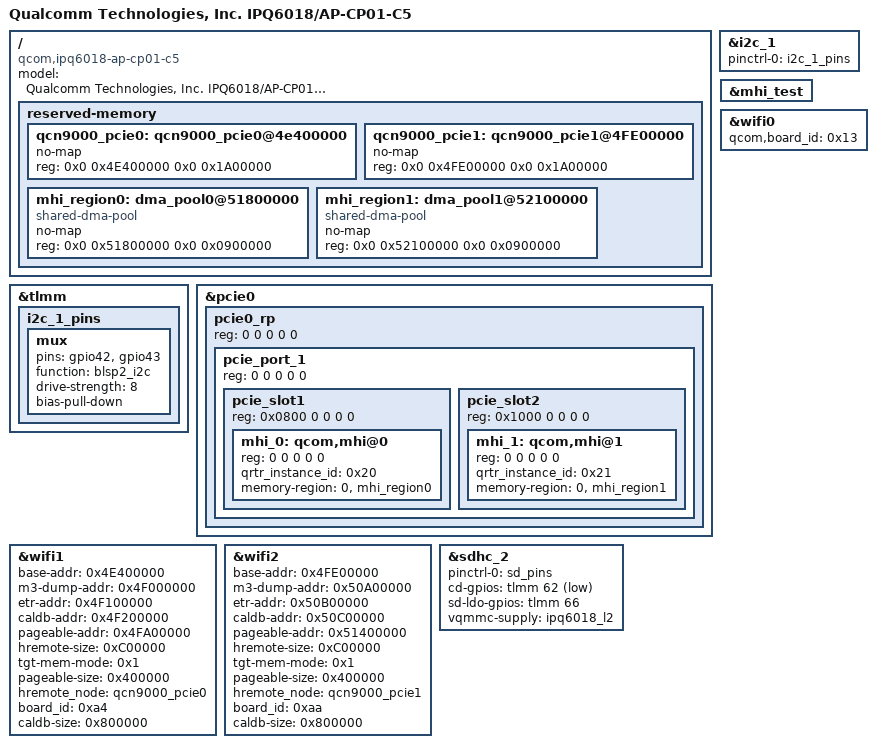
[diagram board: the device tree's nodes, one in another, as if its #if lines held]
/dts-v1/;
/*
 * Copyright (c) 2019, 2021 The Linux Foundation. All rights reserved.
 *
 * Permission to use, copy, modify, and/or distribute this software for any
 * purpose with or without fee is hereby granted, provided that the above
 * copyright notice and this permission notice appear in all copies.
 *
 * THE SOFTWARE IS PROVIDED "AS IS" AND THE AUTHOR DISCLAIMS ALL WARRANTIES
 * WITH REGARD TO THIS SOFTWARE INCLUDING ALL IMPLIED WARRANTIES OF
 * MERCHANTABILITY AND FITNESS. IN NO EVENT SHALL THE AUTHOR BE LIABLE FOR
 * ANY SPECIAL, DIRECT, INDIRECT, OR CONSEQUENTIAL DAMAGES OR ANY DAMAGES
 * WHATSOEVER RESULTING FROM LOSS OF USE, DATA OR PROFITS, WHETHER IN AN
 * ACTION OF CONTRACT, NEGLIGENCE OR OTHER TORTIOUS ACTION, ARISING OUT OF
 * OR IN CONNECTION WITH THE USE OR PERFORMANCE OF THIS SOFTWARE.
 */

#include "ipq6018-cp01.dtsi"
#include "ipq6018-cpr-regulator.dtsi"

/ {
	model = "Qualcomm Technologies, Inc. IPQ6018/AP-CP01-C5";
	compatible = "qcom,ipq6018-ap-cp01-c5", "qcom,ipq6018-ap-cp01", "qcom,ipq6018";

	reserved-memory {

/* No Pine attach in 256M profile */
#if !defined(__IPQ_MEM_PROFILE_256_MB__)
#ifdef __IPQ_MEM_PROFILE_512_MB__
		/*	    512 MB Profile for cp01-c3
		 * +========+==============+=========================+
		 * | Region | Start Offset |          Size           |
		 * +--------+--------------+-------------------------+
		 * |  NSS   |  0x40000000  |          16MB           |
		 * +--------+--------------+-------------------------+
		 * |        |              |                         |
		 * | Linux  |  0x41000000  |         145MB           |
		 * |        |              |                         |
		 * +--------+--------------+-------------------------+
		 * | uboot  |  0x4A100000  |           4MB           |
		 * +--------+--------------+-------------------------+
		 * |  SBL   |  0x4A500000  |           1MB           |
		 * +--------+--------------+-------------------------+
		 * | TZ+HYP |  0x4A600000  |           4MB           |
		 * +--------+--------------+-------------------------+
		 * |  smem  |  0x4AA00000  |           1MB           |
		 * +--------+--------------+-------------------------+
		 * |   Q6   |  0x4AB00000  |          55MB           |
		 * +--------+--------------+-------------------------+
		 * |  QDSS  |  0x4E200000  |           1MB           |
		 * +--------+--------------+-------------------------+
		 * | M3 Dump|  0x4E300000  |           1MB           |
		 * +--------+--------------+-------------------------+
		 * |  Pine0 |  0x4E400000  |          26MB           |
		 * +--------+--------------+-------------------------+
		 * |  Pine1 |  0x4FE00000  |          26MB           |
		 * +--------+--------------+-------------------------+
		 * |  MHI0  |  0x51800000  |           9MB           |
		 * +--------+--------------+-------------------------+
		 * |  MHI1  |  0x52100000  |           9MB           |
		 * +=================================================+
		 * |           Remaining memory for Linux            |
		 * +=================================================+
		 */
		qcn9000_pcie0: qcn9000_pcie0@4e400000 {
			no-map;
			reg = <0x0 0x4E400000 0x0 0x1A00000>;
		};

		qcn9000_pcie1: qcn9000_pcie1@4FE00000 {
			no-map;
			reg = <0x0 0x4FE00000 0x0 0x1A00000>;
		};

#if defined(__CNSS2__)
		mhi_region0: dma_pool0@51800000 {
			compatible = "shared-dma-pool";
			no-map;
			reg = <0x0 0x51800000 0x0 0x0900000>;
		};

		mhi_region1: dma_pool1@52100000 {
			compatible = "shared-dma-pool";
			no-map;
			reg = <0x0 0x52100000 0x0 0x0900000>;
		};
#endif
#else
		/*		  Default Profile
		 * +========+==============+=========================+
		 * | Region | Start Offset |          Size           |
		 * +--------+--------------+-------------------------+
		 * |  NSS   |  0x40000000  |          16MB           |
		 * +--------+--------------+-------------------------+
		 * | Linux  |  0x41000000  |         145MB           |
		 * +--------+--------------+-------------------------+
		 * | uboot  |  0x4A100000  |           4MB           |
		 * +--------+--------------+-------------------------+
		 * |  SBL   |  0x4A500000  |           1MB           |
		 * +--------+--------------+-------------------------+
		 * | TZ+HYP |  0x4A600000  |           4MB           |
		 * +--------+--------------+-------------------------+
		 * |  smem  |  0x4AA00000  |           1MB           |
		 * +--------+--------------+-------------------------+
		 * |   Q6   |  0x4AB00000  |          85MB           |
		 * +--------+--------------+-------------------------+
		 * |  QDSS  |  0x50000000  |           1MB           |
		 * +--------+--------------+-------------------------+
		 * | M3 Dump|  0x50100000  |           1MB           |
		 * +--------+--------------+-------------------------+
		 * |  Pine0 |  0x50200000  |          53MB           |
		 * +--------+--------------+-------------------------+
		 * |  Pine1 |  0x53700000  |          53MB           |
		 * +--------+--------------+-------------------------+
		 * |  MHI0  |  0x56C00000  |           9MB           |
		 * +--------+--------------+-------------------------+
		 * |  MHI1  |  0x57500000  |           9MB           |
		 * +=================================================+
		 * |           Remaining memory for Linux            |
		 * +=================================================+
		 */
		qcn9000_pcie0: qcn9000_pcie0@50200000 {
			no-map;
			reg = <0x0 0x50200000 0x0 0x03500000>;
		};

		qcn9000_pcie1: qcn9000_pcie1@53700000 {
			no-map;
			reg = <0x0 0x53700000 0x0 0x03500000>;
		};

#if defined(__CNSS2__)
		mhi_region0: dma_pool0@56c00000 {
			compatible = "shared-dma-pool";
			no-map;
			reg = <0x0 0x56C00000 0x0 0x00900000>;
		};

		mhi_region1: dma_pool1@57500000 {
			compatible = "shared-dma-pool";
			no-map;
			reg = <0x0 0x57500000 0x0 0x00900000>;
		};
#endif
#endif
#endif
	};
};

&tlmm {
	i2c_1_pins: i2c_1_pins {
		mux {
			pins = "gpio42", "gpio43";
			function = "blsp2_i2c";
			drive-strength = <8>;
			bias-pull-down;
		};
	};
};

&i2c_1 {
	pinctrl-0 = <&i2c_1_pins>;
	pinctrl-names = "default";
	status = "ok";
};

&pcie0 {
	pcie0_rp {
		reg = <0 0 0 0 0>;
		status = "ok";
		device_type = "pci";

		pcie_port_1: pcie_port_1 {
			reg = <0 0 0 0 0>;
			device_type = "pci";

			pcie_slot1: pcie_slot1 {
				reg = <0x0800 0 0 0 0>;
				device_type = "pci";
			};

			pcie_slot2: pcie_slot2 {
				reg = <0x1000 0 0 0 0>;
				device_type = "pci";
			};
		};
	};
};

&pcie_port_1 {
	status = "ok";
};

&pcie_slot1 {
	status = "ok";

	mhi_0: qcom,mhi@0 {
		reg = <0 0 0 0 0 >;
		qrtr_instance_id = <0x20>;
#if defined(__CNSS2__)
#if !defined(__IPQ_MEM_PROFILE_256_MB__)
		memory-region = <0>,<&mhi_region0>;
#endif
#endif
	};
};

&pcie_slot2 {
	status = "ok";

	mhi_1: qcom,mhi@1 {
		reg = <0 0 0 0 0 >;
		qrtr_instance_id = <0x21>;
#if defined(__CNSS2__)
#if !defined(__IPQ_MEM_PROFILE_256_MB__)
		memory-region = <0>,<&mhi_region1>;
#endif
#endif
	};
};

&mhi_test {
       status = "ok";
};

&wifi0 {
	qcom,board_id = <0x13>;
	status = "ok";
};

/* No support for QCN9000 in 256M profile */
#if !defined(__IPQ_MEM_PROFILE_256_MB__)
&wifi1 {
#ifdef __IPQ_MEM_PROFILE_512_MB__
	/* QCN9000 tgt-mem-mode=1 layout - 26MB
	 * +=========+==============+=========+
	 * |  Region | Start Offset |   Size  |
	 * +---------+--------------+---------+
	 * | HREMOTE |  0x4E400000  |   12MB  |
	 * +---------+--------------+---------+
	 * | M3 Dump |  0x4F000000  |   1MB   |
	 * +---------+--------------+---------+
	 * |   ETR   |  0x4F100000  |   1MB   |
	 * +---------+--------------+---------+
	 * |  Caldb  |  0x4F200000  |   8MB   |
	 * +---------+--------------+---------+
	 * | Pageable|  0x4FA00000  |   4MB   |
	 * +==================================+
	 */
	base-addr = <0x4E400000>;
	m3-dump-addr = <0x4F000000>;
	etr-addr = <0x4F100000>;
	caldb-addr = <0x4F200000>;
	pageable-addr = <0x4FA00000>;
	hremote-size = <0xC00000>;
	tgt-mem-mode = <0x1>;
	pageable-size = <0x400000>;
#else
	/* QCN9000 tgt-mem-mode=0 layout - 45MB
	 * +=========+==============+=========+
	 * |  Region | Start Offset |   Size  |
	 * +---------+--------------+---------+
	 * | HREMOTE |  0x50200000  |   35MB  |
	 * +---------+--------------+---------+
	 * | M3 Dump |  0x52500000  |   1MB   |
	 * +---------+--------------+---------+
	 * |   ETR   |  0x52600000  |   1MB   |
	 * +---------+--------------+---------+
	 * |  Caldb  |  0x52700000  |   8MB   |
	 * +---------+--------------+---------+
	 * | Pageable|  0x52F00000  |   8MB   |
	 * +==================================+
	 */
	base-addr = <0x50200000>;
	m3-dump-addr = <0x52500000>;
	etr-addr = <0x52600000>;
	caldb-addr = <0x52700000>;
	pageable-addr = <0x52F00000>;
	hremote-size = <0x2300000>;
	tgt-mem-mode = <0x0>;
	pageable-size = <0x800000>;
#endif
	/* QCN9000 6Ghz Radio */
	hremote_node = <&qcn9000_pcie0>;
	board_id = <0xa4>;
	caldb-size = <0x800000>;
	status = "ok";
};

&wifi2 {
#ifdef __IPQ_MEM_PROFILE_512_MB__
	/* QCN9000 tgt-mem-mode=1 layout - 26MB
	 * +=========+==============+=========+
	 * |  Region | Start Offset |   Size  |
	 * +---------+--------------+---------+
	 * | HREMOTE |  0x4FE00000  |   12MB  |
	 * +---------+--------------+---------+
	 * | M3 Dump |  0x50A00000  |   1MB   |
	 * +---------+--------------+---------+
	 * |   ETR   |  0x50B00000  |   1MB   |
	 * +---------+--------------+---------+
	 * |  Caldb  |  0x50C00000  |   8MB   |
	 * +---------+--------------+---------+
	 * | Pageable|  0x51400000  |   4MB   |
	 * +==================================+
	 */
	base-addr = <0x4FE00000>;
	m3-dump-addr = <0x50A00000>;
	etr-addr = <0x50B00000>;
	caldb-addr = <0x50C00000>;
	pageable-addr = <0x51400000>;
	hremote-size = <0xC00000>;
	tgt-mem-mode = <0x1>;
	pageable-size = <0x400000>;
#else
	/* QCN9000 tgt-mem-mode=0 layout - 45MB
	 * +=========+==============+=========+
	 * |  Region | Start Offset |   Size  |
	 * +---------+--------------+---------+
	 * | HREMOTE |  0x53700000  |   35MB  |
	 * +---------+--------------+---------+
	 * | M3 Dump |  0x55A00000  |   1MB   |
	 * +---------+--------------+---------+
	 * |   ETR   |  0x55B00000  |   1MB   |
	 * +---------+--------------+---------+
	 * |  Caldb  |  0x55C00000  |   8MB   |
	 * +---------+--------------+---------+
	 * | Pageable|  0x56400000  |   8MB   |
	 * +==================================+
	 */
	base-addr = <0x53700000>;
	m3-dump-addr = <0x55A00000>;
	etr-addr = <0x55B00000>;
	caldb-addr = <0x55C00000>;
	pageable-addr = <0x56400000>;
	hremote-size = <0x2300000>;
	tgt-mem-mode = <0x0>;
	pageable-size = <0x800000>;
#endif
	/* QCN9000 6G Scan Radio */
	hremote_node = <&qcn9000_pcie1>;
	board_id = <0xaa>;
	caldb-size = <0x800000>;
	status = "ok";
};
#endif

&sdhc_2 {
	pinctrl-0 = <&sd_pins>;
	pinctrl-names = "default";
	cd-gpios = <&tlmm 62 1>;
	sd-ldo-gpios = <&tlmm 66 0>;
	vqmmc-supply = <&ipq6018_l2>;
	status = "ok";
};
